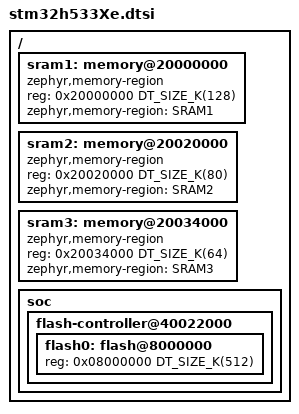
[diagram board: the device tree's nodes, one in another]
/*
 * Copyright (c) 2024 STMicroelectronics
 *
 * SPDX-License-Identifier: Apache-2.0
 */
#include <st/h5/stm32h533.dtsi>

/ {
	sram1: memory@20000000 {
		compatible = "zephyr,memory-region", "mmio-sram";
		reg = <0x20000000 DT_SIZE_K(128)>;
		zephyr,memory-region = "SRAM1";
	};

	sram2: memory@20020000 {
		compatible = "zephyr,memory-region", "mmio-sram";
		reg = <0x20020000 DT_SIZE_K(80)>;
		zephyr,memory-region = "SRAM2";
	};

	sram3: memory@20034000 {
		compatible = "zephyr,memory-region", "mmio-sram";
		reg = <0x20034000 DT_SIZE_K(64)>;
		zephyr,memory-region = "SRAM3";
	};

	soc {
		flash-controller@40022000 {
			flash0: flash@8000000 {
				reg = <0x08000000 DT_SIZE_K(512)>;
			};
		};
	};
};
